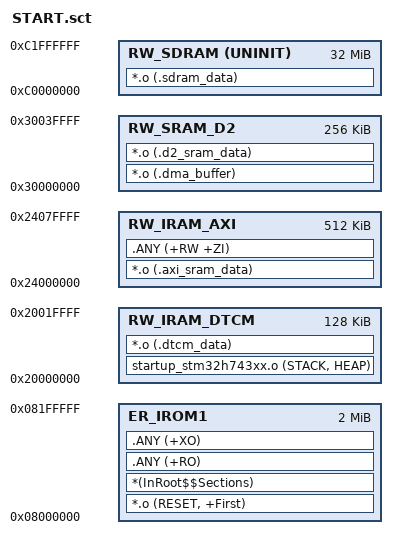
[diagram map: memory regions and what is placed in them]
; STM32H743 AC5 Scatter File (mirror)
; Keep this file in sync with START/MDK/START.sct.

LR_IROM1 0x08000000 0x00200000  {
  ER_IROM1 0x08000000 0x00200000  {
   *.o (RESET, +First)
   *(InRoot$$Sections)
   .ANY (+RO)
   .ANY (+XO)
  }

  RW_IRAM_DTCM 0x20000000 0x00020000  {
   startup_stm32h743xx.o (STACK, HEAP)
   *.o (.dtcm_data)
  }

  RW_IRAM_AXI 0x24000000 0x00080000  {
   *.o (.axi_sram_data)
   .ANY (+RW +ZI)
  }

  RW_SRAM_D2 0x30000000 0x00040000  {
   *.o (.dma_buffer)
   *.o (.d2_sram_data)
  }

  RW_SDRAM 0xC0000000 UNINIT 0x02000000  {
   *.o (.sdram_data)
  }
}
